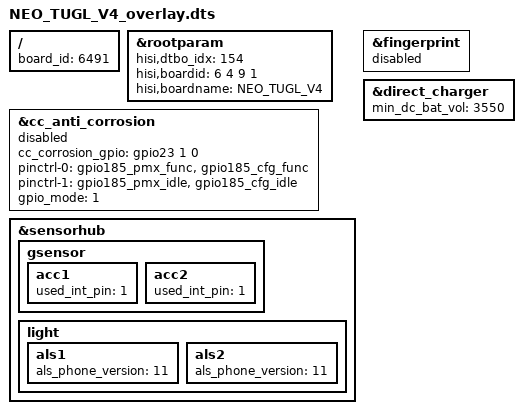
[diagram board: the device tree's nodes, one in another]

/**
 * Copyright (C) 2014 Hisilicon Ltd.
 *
 *  This program is free software; you can redistribute it and/or modify
 *  it under the terms of the GNU General Public License version 2 as
 *  publishhed by the Free Software Foundation.
 */

/dts-v1/;
/plugin/;
/include/ "NEO_TUGL_V3_overlay.dtsi"
/include/ "NEO_TUGL_V4_overlay_module_amba.dts"

/ {
        board_id = <6491>;
};

&rootparam {
        hisi,dtbo_idx = <154>;
    hisi,boardid = <6 4 9 1>;
    hisi,boardname = "NEO_TUGL_V4";
};


&cc_anti_corrosion {
	cc_corrosion_gpio = <&gpio23 1 0>;
	pinctrl-0 = <&gpio185_pmx_func &gpio185_cfg_func>;
	pinctrl-1 = <&gpio185_pmx_idle &gpio185_cfg_idle>;
	gpio_mode = <1>;
	status = "disabled";
};

&sensorhub {
	gsensor {
		acc1 {
			used_int_pin =<1>;
		};
		acc2 {
			used_int_pin =<1>;
		};
	};

	light{
		als1{
			als_phone_version = <11>;
		};
		als2{
			als_phone_version = <11>;
		};
	};
};
&fingerprint {
	status = "disabled";
};
&direct_charger {
	min_dc_bat_vol = <3550>;
};
